# STM32WL3xx register map
File version: 1.0
Registers are 32-bit, read-write, reset 0x0 unless marked. A register's access mark holds for its fields unless they carry their own. Offsets are from the block's base; lines under a group give offsets from that group; [hi:lo] are bit positions; {n}, {i} and the like mark numbered series; 'fields as' and 'values as' point back to an identical list; <NAME> marks a mode.

## Memory map
0x40000000 SYSCFG — System configuration controller (SYSCFG)
0x40001000 FLASH — FLASH (FLASH)
0x40002000 TIM2 — Advanced-timers (TIM)
0x40003000 IWDG — Independent watchdog (IWDG)
0x40004000 RTC — Real-time clock (RTC)
0x40005000 TIM16 — Advanced-timers (TIM)
0x40006000 DAC1 — Digital to Analog Converter (DAC)
0x40007000 LCD — Liquid crystal display controller (LCD)
0x40008000 DBGMCU — MCU debug component (DBGMCU)
0x40009000 COMP1 — Comparator (COMP)
0x4000A000 LCSC — LC Sensor Controller (LCSC)
0x41000000 I2C1 — Inter-integrated circuit (I2C)
0x41001000 I2C2 — Inter-integrated circuit (I2C)
0x41002000 SPI1 — Serial peripheral interface/Inter-IC sound (SPI)
0x41004000 USART1 — Universal synchronous asynchronous receiver transmitter (USART)
0x41005000 LPUART1 — Universal synchronous asynchronous receiver transmitter (USART)
0x41006000 ADC1 — ADC (ADC)
0x41007000 SPI3 — Serial peripheral interface/Inter-IC sound (SPI)
0x48000000 GPIOA — General-purpose I/Os (GPIO)
0x48100000 GPIOB — General-purpose I/Os (GPIO)
0x48200000 CRC — Cyclic redundancy check calculation unit (CRC)
0x48400000 RCC — Reset and clock control (RCC)
0x48500000 PWR — Power control (PWR)
0x48600000 RNG — Random number generator (RNG)
0x48700000 DMA1 — Direct memory access controller (DMA)
0x48800000 DMAMUX1 — DMA Multiplexer
0x48900000 AES — Advanced encryption standard hardware accelerator (AES)
0x49000000 MR_SUBG_RADIO
0x49000400 MR_SUBG_GLOB_STATIC — MR_SUBG Global Static
0x49000500 MR_SUBG_GLOB_DYNAMIC — MR_SUBG Global Dynamic
0x49000600 MR_SUBG_GLOB_STATUS — MR_SUBG Global Status
0x49000700 MR_SUBG_GLOB_MISC — MR_SUBG Global Misc
0x49000780 MR_SUBG_GLOB_RETAINED — MR_SUBG Global Retained
0x49001000 LPAWUR — Low Power Autonomous Wakeup Radio IP

## Interrupts
0 FLASH — 0 NVM interrupt
1 RCC — 1 RCC interrupt
3 I2C1 — 3 I2C1 interrupt
4 I2C2 — 4 I2C2 interrupt
5 SPI1 — 5 SPI1 interrupt
7 SPI3 — 7 SPI3 interrupt
8 USART1 — 8 USART interrupt
9 LPUART1 — 9 Low Power UART interrupt
10 TIM2 — 10 Timer 2 interrupt
11 RTC — 11 RTC interrupt
12 ADC (ADC1) — 12 ADC interrupt
13 AES — 13 AES interrupt
15 GPIOA — 15 GPIOA interrupt
16 GPIOB — 16 GPIOB interrupt
17 DMA (DMA1) — 17 DMA interrupt
18 LPAWUR — 18 LPAWUR interrupt
19 COMP1 — 19 Comp interrupt through SYSCFGBLE
25 DAC (DAC1) — 25 DAC interrupt
26 TIM16 — 26 TIM16 interrupt
27 LCD — 27 LCD interrupt
28 LCSC — 28 LCSC interrupt
29 LCSC_LC_ACTIVITY (LCSC) — 28 LCSC LC activity interrupt

## SYSCFG — System configuration controller (SYSCFG)
Base 0x40000000
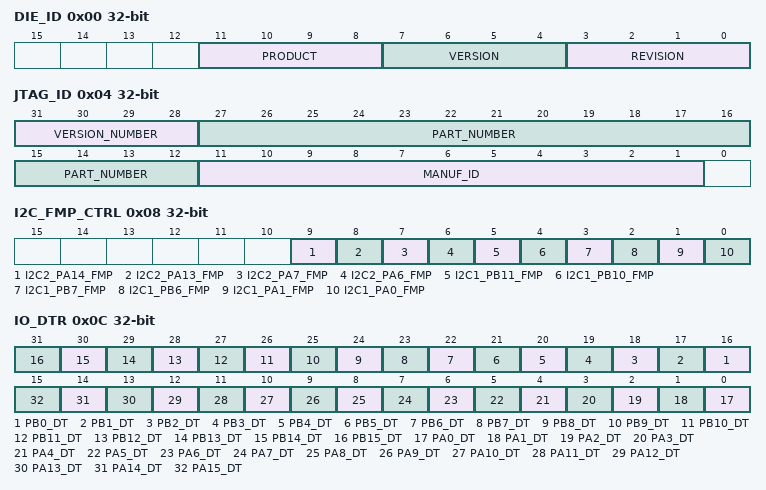
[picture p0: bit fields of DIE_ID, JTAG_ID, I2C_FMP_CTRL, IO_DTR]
0x00 DIE_ID — (@ 0x00000000) Die ID register
  [11:8] PRODUCT, [7:4] VERSION, [3:0] REVISION
0x04 JTAG_ID — (@ 0x00000004) JTAG ID register
  [31:28] VERSION_NUMBER, [27:12] PART_NUMBER, [11:1] MANUF_ID
0x08 I2C_FMP_CTRL — (@ 0x00000008) I2C Fast-Mode Plus pin capability control register
  [9] I2C2_PA14_FMP, [8] I2C2_PA13_FMP, [7] I2C2_PA7_FMP, [6] I2C2_PA6_FMP, [5] I2C1_PB11_FMP, [4] I2C1_PB10_FMP, [3] I2C1_PB7_FMP, [2] I2C1_PB6_FMP, [1] I2C1_PA1_FMP, [0] I2C1_PA0_FMP
0x0C IO_DTR — (@ 0x0000000C) I/O Interrupt detection type register
  [n+16] PB{n}_DT (n=0..15), [n] PA{n}_DT (n=0..15)
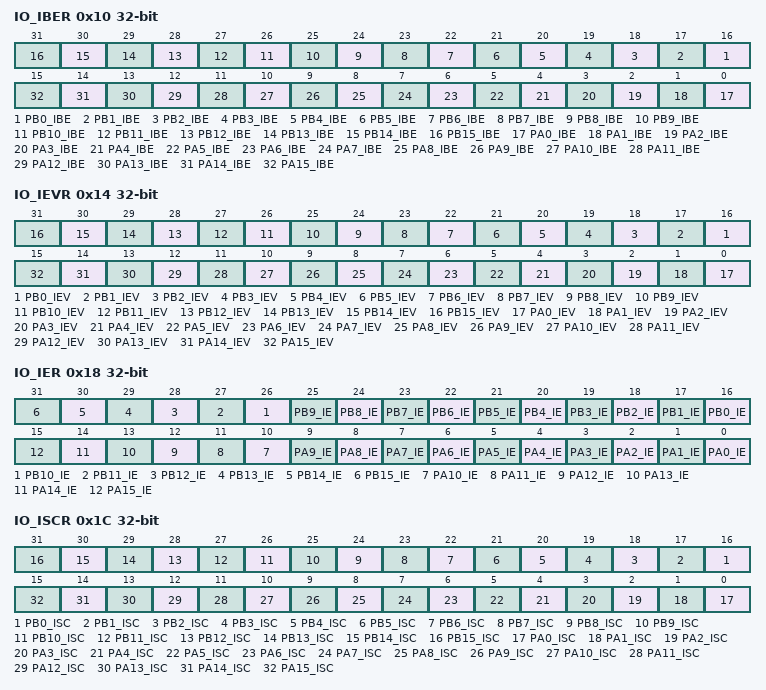
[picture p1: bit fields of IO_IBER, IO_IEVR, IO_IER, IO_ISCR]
0x10 IO_IBER — (@ 0x00000010) I/O Interrupt Edge register
  [n+16] PB{n}_IBE (n=0..15), [n] PA{n}_IBE (n=0..15)
0x14 IO_IEVR — (@ 0x00000014) I/O Interrupt polarity event register
  [n+16] PB{n}_IEV (n=0..15), [n] PA{n}_IEV (n=0..15)
0x18 IO_IER — (@ 0x00000018) I/O Interrupt Enable register
  [n+16] PB{n}_IE (n=0..15), [n] PA{n}_IE (n=0..15)
0x1C IO_ISCR — (@ 0x0000001C) I/O Interrupt Status and Clear register
  [n+16] PB{n}_ISC (n=0..15), [n] PA{n}_ISC (n=0..15)
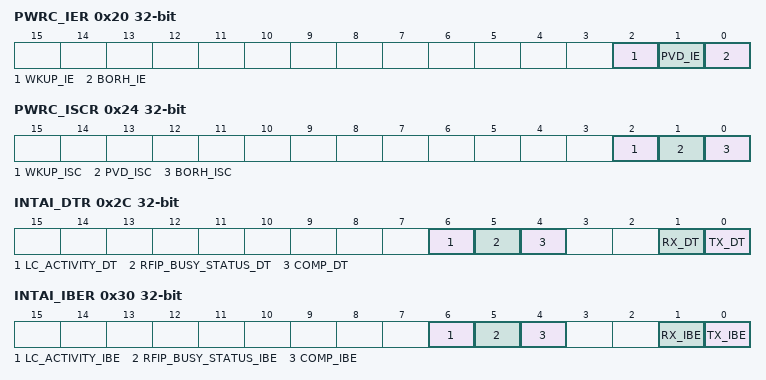
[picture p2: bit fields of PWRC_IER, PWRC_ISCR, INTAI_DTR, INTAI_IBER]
0x20 PWRC_IER — (@ 0x00000020) Power Controller Interrupt Enable register
  [2] WKUP_IE, [1] PVD_IE, [0] BORH_IE
0x24 PWRC_ISCR — (@ 0x00000024) Power Controller Interrupt Status and Clear register
  [2] WKUP_ISC, [1] PVD_ISC, [0] BORH_ISC
0x28 GPIO_SWA_CTRL — (@ 0x00000028) I/O analog switch control register
  [0] ATB1_nPVD
0x2C INTAI_DTR — (@ 0x0000002C) Internal asynchronous interrupt detection type register
  [6] LC_ACTIVITY_DT, [5] RFIP_BUSY_STATUS_DT, [4] COMP_DT, [1] RX_DT, [0] TX_DT
0x30 INTAI_IBER — (@ 0x00000030) Internal asynchronous interrupt edge register
  [6] LC_ACTIVITY_IBE
    0=SINGLE (Detection on single edge); 1=BOTH (Detection on both edges)
  [5] RFIP_BUSY_STATUS_IBE
  [4] COMP_IBE
  [1] RX_IBE
  [0] TX_IBE
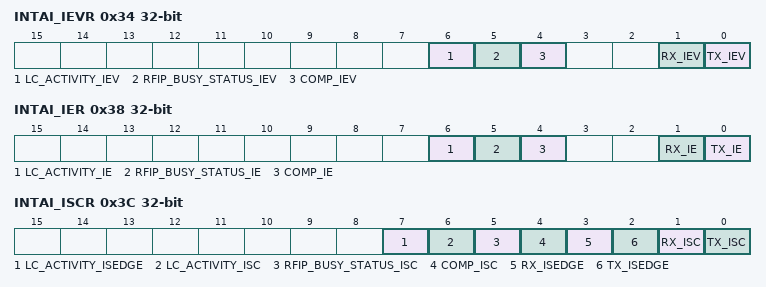
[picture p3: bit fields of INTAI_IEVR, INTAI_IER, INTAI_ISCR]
0x34 INTAI_IEVR — (@ 0x00000034) Internal asynchronous interrupt polarity event register
  [6] LC_ACTIVITY_IEV
    0=FALLING (Detection on falling edge / low level); 1=RISING (Detection on rising edge / high level)
  [5] RFIP_BUSY_STATUS_IEV
  [4] COMP_IEV
  [1] RX_IEV
  [0] TX_IEV
0x38 INTAI_IER — (@ 0x00000038) Internal asynchronous interrupt enable register
  [6] LC_ACTIVITY_IE, [5] RFIP_BUSY_STATUS_IE, [4] COMP_IE, [1] RX_IE, [0] TX_IE
0x3C INTAI_ISCR — (@ 0x0000003C) Internal asynchronous interrupt detection status and clear register
  [7] LC_ACTIVITY_ISEDGE, [6] LC_ACTIVITY_ISC, [5] RFIP_BUSY_STATUS_ISC, [4] COMP_ISC, [3] RX_ISEDGE, [2] TX_ISEDGE, [1] RX_ISC, [0] TX_ISC
0x40 SR1 — (@ 0x00000040) SYSCFG status register 1
  [5] RFIP_BUSY_STATUS
